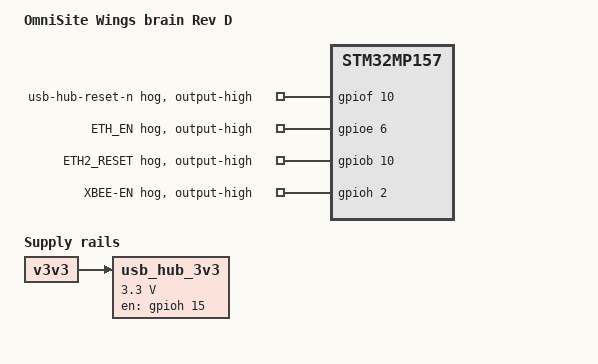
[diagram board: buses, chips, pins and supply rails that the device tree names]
// SPDX-License-Identifier: GPL-2.0+ OR BSD-3-Clause
/* Wings brain board Rev D. Keep the existing DVK/Rev C description intact. */
#include "ccmp157-dvk.dts"

/ {
	model = "OmniSite Wings brain Rev D";
	compatible = "omnisite,wings-revd", "digi,ccmp15-dvk",
		     "digi,ccmp15", "digi,ccmp1", "st,stm32mp157";

	usb_hub_3v3: regulator-usb-hub-3v3 {
		compatible = "regulator-fixed";
		regulator-name = "usb-hub-3v3";
		regulator-min-microvolt = <3300000>;
		regulator-max-microvolt = <3300000>;
		vin-supply = <&v3v3>;
		/* Rev D moved USB_HUB_EN from PA10 to PH15 (SOM L1). */
		gpio = <&gpioh 15 GPIO_ACTIVE_HIGH>;
		enable-active-high;
		regulator-boot-on;
		regulator-always-on;
		startup-delay-us = <20000>;
	};
};

&display_bl {
	/* Flags 0 select normal polarity in the 5.15 PWM binding. Keep 8 ms. */
	pwms = <&pwm2 0 8000000 0>;
};

&gpiof {
	usb-hub-reset {
		gpio-hog;
		/* PF10 (SOM A9) is RESET_N, not a parallel LCD DE signal here. */
		gpios = <10 GPIO_ACTIVE_HIGH>;
		output-high;
		line-name = "usb-hub-reset-n";
	};
};

/* Retain board controls previously supplied by the V1 carrier overlay.
 * Rev D cannot use that whole overlay because USB_HUB_EN moved from PA10.
 * GPIO hog direction setup selects GPIO mode. Do not also put these pins
 * in the controller default pinctrl state: STM32 strict ownership rejects
 * the second request made by gpio_stub_drv after the hogs are registered.
 */
&gpioe {
    eth_en: eth-en {
        gpio-hog;
        gpios = <6 GPIO_ACTIVE_HIGH>;
        output-high;
        line-name = "ETH_EN";
    };
};

&gpiob {
    eth2_reset: eth2-reset {
        gpio-hog;
        gpios = <10 GPIO_ACTIVE_HIGH>;
        output-high;
        line-name = "ETH2_RESET";
    };
};

&gpioh {
    xbee_en: xbee_en {
        gpio-hog;
        gpios = <2 GPIO_ACTIVE_HIGH>;
        output-high;
        line-name = "XBEE-EN";
    };
};

/* WingsApp requests GPIOZ line 2 as an output through gpiolib. That request
 * selects GPIO mode; leave the mux and line unclaimed until userspace owns it.
 */
